VERSION "created by canmatrix"

NS_ :

BS_:

BU_: BMS BMU

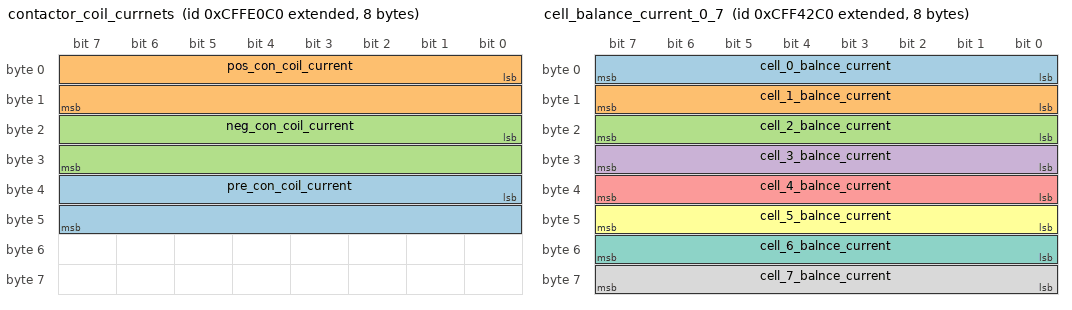
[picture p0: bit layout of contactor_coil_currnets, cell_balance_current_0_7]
BO_ 2365579456 contactor_coil_currnets: 8 Vector__XXX
 SG_ pre_con_coil_current : 32|16@1+ (0.001,0) [0|65.535] "A" Vector__XXX
 SG_ pos_con_coil_current : 0|16@1+ (0.001,0) [0|65.535] "A" Vector__XXX
 SG_ neg_con_coil_current : 16|16@1+ (0.001,0) [0|65.535] "A" Vector__XXX

BO_ 2365583552 safety_app_faults_1: 8 Vector__XXX
 SG_ f_UnprivilegedApplication : 20|1@1+ (1,0) [0|1] "" Vector__XXX
 SG_ f_ServiceDisconnect : 19|1@1+ (1,0) [0|1] "" Vector__XXX
 SG_ f_PackUndervoltage : 5|1@1+ (1,0) [0|1] "" Vector__XXX
 SG_ f_PackOvervoltage : 4|1@1+ (1,0) [0|1] "" Vector__XXX
 SG_ f_PackOvercurrentDischarge : 7|1@1+ (1,0) [0|1] "" Vector__XXX
 SG_ f_PackOvercurrentCharge : 6|1@1+ (1,0) [0|1] "" Vector__XXX
 SG_ f_MasterBoard : 13|1@1+ (1,0) [0|1] "" Vector__XXX
 SG_ f_IsolationLeakage : 12|1@1+ (1,0) [0|1] "" Vector__XXX
 SG_ f_ImminentContactorOpening : 17|1@1+ (1,0) [0|1] "" Vector__XXX
 SG_ f_Hvil : 10|1@1+ (1,0) [0|1] "" Vector__XXX
 SG_ f_FailedVoltage : 9|1@1+ (1,0) [0|1] "" Vector__XXX
 SG_ f_FailedThermistor : 8|1@1+ (1,0) [0|1] "" Vector__XXX
 SG_ f_EStop : 18|1@1+ (1,0) [0|1] "" Vector__XXX
 SG_ f_ContactorWelded : 16|1@1+ (1,0) [0|1] "" Vector__XXX
 SG_ f_ContactorOpen : 15|1@1+ (1,0) [0|1] "" Vector__XXX
 SG_ f_Communication : 11|1@1+ (1,0) [0|1] "" Vector__XXX
 SG_ f_CommandTimeout : 14|1@1+ (1,0) [0|1] "" Vector__XXX
 SG_ f_CellUndervoltage : 1|1@1+ (1,0) [0|1] "" Vector__XXX
 SG_ f_CellUndertemp : 3|1@1+ (1,0) [0|1] "" Vector__XXX
 SG_ f_CellOvervoltage : 0|1@1+ (1,0) [0|1] "" Vector__XXX
 SG_ f_CellOvertemp : 2|1@1+ (1,0) [0|1] "" Vector__XXX

BO_ 2365539008 cell_balance_current_0_7: 8 Vector__XXX
 SG_ cell_0_balnce_current : 0|8@1+ (0.05,0) [0|12.75] "A" Vector__XXX
 SG_ cell_1_balnce_current : 8|8@1+ (0.05,0) [0|12.75] "A" Vector__XXX
 SG_ cell_2_balnce_current : 16|8@1+ (0.05,0) [0|12.75] "A" Vector__XXX
 SG_ cell_3_balnce_current : 24|8@1+ (0.05,0) [0|12.75] "A" Vector__XXX
 SG_ cell_4_balnce_current : 32|8@1+ (0.05,0) [0|12.75] "A" Vector__XXX
 SG_ cell_5_balnce_current : 40|8@1+ (0.05,0) [0|12.75] "A" Vector__XXX
 SG_ cell_6_balnce_current : 48|8@1+ (0.05,0) [0|12.75] "A" Vector__XXX
 SG_ cell_7_balnce_current : 56|8@1+ (0.05,0) [0|12.75] "A" Vector__XXX

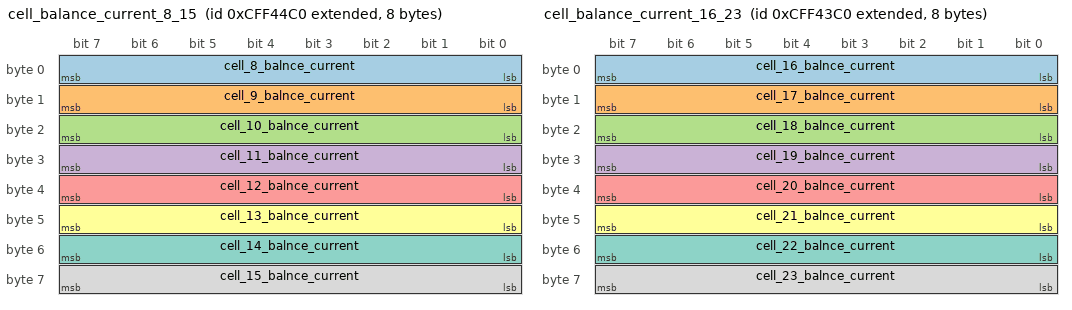
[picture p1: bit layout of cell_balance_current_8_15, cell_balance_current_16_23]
BO_ 2365539520 cell_balance_current_8_15: 8 Vector__XXX
 SG_ cell_8_balnce_current : 0|8@1+ (0.05,0) [0|12.75] "A" Vector__XXX
 SG_ cell_9_balnce_current : 8|8@1+ (0.05,0) [0|12.75] "A" Vector__XXX
 SG_ cell_10_balnce_current : 16|8@1+ (0.05,0) [0|12.75] "A" Vector__XXX
 SG_ cell_11_balnce_current : 24|8@1+ (0.05,0) [0|12.75] "A" Vector__XXX
 SG_ cell_12_balnce_current : 32|8@1+ (0.05,0) [0|12.75] "A" Vector__XXX
 SG_ cell_13_balnce_current : 40|8@1+ (0.05,0) [0|12.75] "A" Vector__XXX
 SG_ cell_14_balnce_current : 48|8@1+ (0.05,0) [0|12.75] "A" Vector__XXX
 SG_ cell_15_balnce_current : 56|8@1+ (0.05,0) [0|12.75] "A" Vector__XXX

BO_ 2365539264 cell_balance_current_16_23: 8 Vector__XXX
 SG_ cell_16_balnce_current : 0|8@1+ (0.05,0) [0|12.75] "A" Vector__XXX
 SG_ cell_17_balnce_current : 8|8@1+ (0.05,0) [0|12.75] "A" Vector__XXX
 SG_ cell_18_balnce_current : 16|8@1+ (0.05,0) [0|12.75] "A" Vector__XXX
 SG_ cell_19_balnce_current : 24|8@1+ (0.05,0) [0|12.75] "A" Vector__XXX
 SG_ cell_20_balnce_current : 32|8@1+ (0.05,0) [0|12.75] "A" Vector__XXX
 SG_ cell_21_balnce_current : 40|8@1+ (0.05,0) [0|12.75] "A" Vector__XXX
 SG_ cell_22_balnce_current : 48|8@1+ (0.05,0) [0|12.75] "A" Vector__XXX
 SG_ cell_23_balnce_current : 56|8@1+ (0.05,0) [0|12.75] "A" Vector__XXX

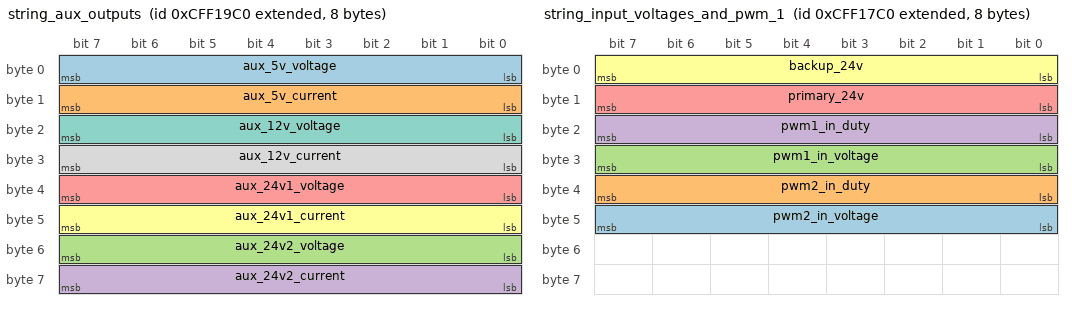
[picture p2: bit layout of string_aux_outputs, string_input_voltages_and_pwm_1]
BO_ 2365528512 string_aux_outputs: 8 Vector__XXX
 SG_ aux_5v_voltage : 0|8@1+ (0.15,0) [0|38.25] "A" Vector__XXX
 SG_ aux_5v_current : 8|8@1+ (0.15,0) [0|38.25] "A" Vector__XXX
 SG_ aux_24v2_voltage : 48|8@1+ (0.15,0) [0|38.25] "A" Vector__XXX
 SG_ aux_24v2_current : 56|8@1+ (0.15,0) [0|38.25] "A" Vector__XXX
 SG_ aux_24v1_voltage : 32|8@1+ (0.15,0) [0|38.25] "A" Vector__XXX
 SG_ aux_24v1_current : 40|8@1+ (0.15,0) [0|38.25] "A" Vector__XXX
 SG_ aux_12v_voltage : 16|8@1+ (0.15,0) [0|38.25] "A" Vector__XXX
 SG_ aux_12v_current : 24|8@1+ (0.15,0) [0|38.25] "A" Vector__XXX

BO_ 2365528256 string_input_voltages_and_pwm_2: 8 Vector__XXX
 SG_ pwm2_in_freq : 32|32@1+ (1,0) [0|65535] "A" Vector__XXX
 SG_ pwm1_in_freq : 0|32@1+ (1,0) [0|65535] "A" Vector__XXX

BO_ 2365528000 string_input_voltages_and_pwm_1: 8 Vector__XXX
 SG_ pwm2_in_voltage : 40|8@1+ (0.15,0) [0|38.25] "A" Vector__XXX
 SG_ pwm2_in_duty : 32|8@1+ (0.5,0) [0|127.5] "A" Vector__XXX
 SG_ pwm1_in_voltage : 24|8@1+ (0.15,0) [0|38.25] "A" Vector__XXX
 SG_ pwm1_in_duty : 16|8@1+ (0.5,0) [0|127.5] "A" Vector__XXX
 SG_ primary_24v : 8|8@1+ (0.15,0) [0|38.25] "A" Vector__XXX
 SG_ backup_24v : 0|8@1+ (0.15,0) [0|38.25] "A" Vector__XXX

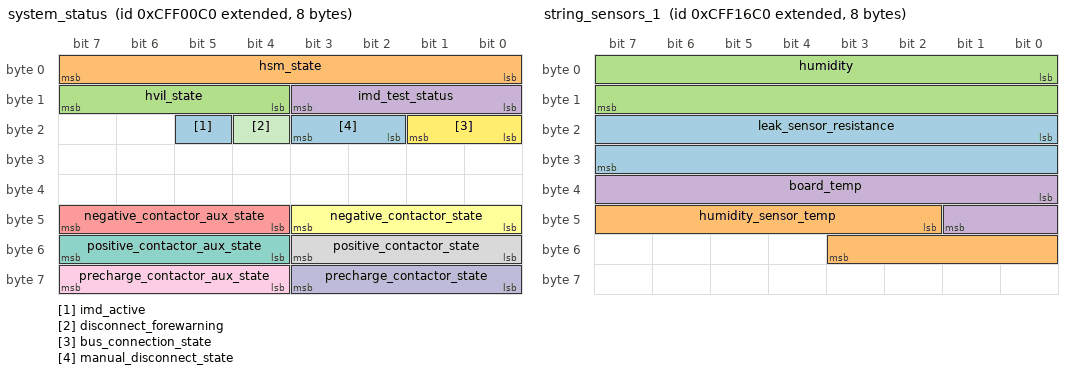
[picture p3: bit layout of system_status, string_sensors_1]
BO_ 2365522112 system_status: 8 BMS
 SG_ imd_active : 21|1@1+ (1,0) [0|1] "C" Vector__XXX
 SG_ hsm_state : 0|8@1+ (1,0) [0|255] ""  BMU
 SG_ hvil_state : 12|4@1+ (1,0) [0|15] ""  BMU
 SG_ imd_test_status : 8|4@1+ (1,0) [0|15] ""  BMU
 SG_ negative_contactor_aux_state : 44|4@1+ (1,0) [0|15] ""  BMU
 SG_ negative_contactor_state : 40|4@1+ (1,0) [0|15] ""  BMU
 SG_ positive_contactor_aux_state : 52|4@1+ (1,0) [0|15] ""  BMU
 SG_ positive_contactor_state : 48|4@1+ (1,0) [0|15] ""  BMU
 SG_ precharge_contactor_aux_state : 60|4@1+ (1,0) [0|15] ""  BMU
 SG_ precharge_contactor_state : 56|4@1+ (1,0) [0|15] ""  BMU
 SG_ disconnect_forewarning : 20|1@1+ (1,0) [0|1] ""  BMU
 SG_ bus_connection_state : 16|2@1+ (1,0) [0|3] "" Vector__XXX
 SG_ manual_disconnect_state : 18|2@1+ (1,0) [0|3] "" Vector__XXX

BO_ 2365527744 string_sensors_1: 8 Vector__XXX
 SG_ leak_sensor_resistance : 16|16@1+ (0.0025,0) [0|163.8375] "" Vector__XXX
 SG_ humidity_sensor_temp : 42|10@1+ (0.2,-50) [-50|154.6] "" Vector__XXX
 SG_ humidity : 0|16@1+ (0.0025,0) [0|163.8375] "" Vector__XXX
 SG_ board_temp : 32|10@1+ (0.2,-50) [-50|154.6] "" Vector__XXX

BO_ 2365527488 string_ntc_temps_7_8: 8 Vector__XXX
 SG_ ntc_temp_8 : 20|10@1+ (0.2,-50) [-50|154.6] "" Vector__XXX
 SG_ ntc_temp_7 : 10|10@1+ (0.2,-50) [-50|154.6] "" Vector__XXX

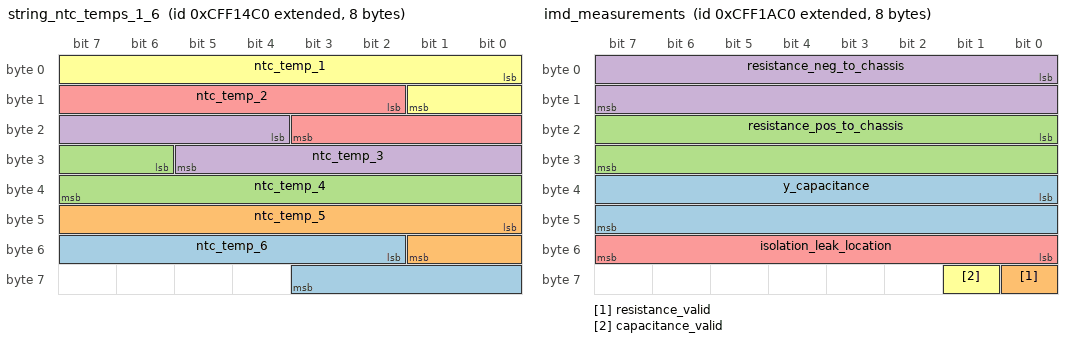
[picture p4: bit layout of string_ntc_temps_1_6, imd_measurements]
BO_ 2365527232 string_ntc_temps_1_6: 8 Vector__XXX
 SG_ ntc_temp_6 : 50|10@1+ (0.2,-50) [-50|154.6] "" Vector__XXX
 SG_ ntc_temp_5 : 40|10@1+ (0.2,-50) [-50|154.6] "" Vector__XXX
 SG_ ntc_temp_4 : 30|10@1+ (0.2,-50) [-50|154.6] "" Vector__XXX
 SG_ ntc_temp_3 : 20|10@1+ (0.2,-50) [-50|154.6] "" Vector__XXX
 SG_ ntc_temp_2 : 10|10@1+ (0.2,-50) [-50|154.6] "" Vector__XXX
 SG_ ntc_temp_1 : 0|10@1+ (0.2,-50) [-50|154.6] "" Vector__XXX

BO_ 2365528768 imd_measurements: 8 Vector__XXX
 SG_ y_capacitance : 32|16@1+ (1,0) [0|65535] "A" Vector__XXX
 SG_ resistance_valid : 56|1@1+ (1,0) [0|1] "C" Vector__XXX
 SG_ resistance_pos_to_chassis : 16|16@1+ (100,0) [0|6553500] "A" Vector__XXX
 SG_ resistance_neg_to_chassis : 0|16@1+ (100,0) [0|6553500] "A" Vector__XXX
 SG_ isolation_leak_location : 48|8@1+ (0.005,0) [0|1.275] "" Vector__XXX
 SG_ capacitance_valid : 57|1@1+ (1,0) [0|1] "C" Vector__XXX

BO_ 2365538752 cell_balancing_status_0_23: 8 Vector__XXX
 SG_ cell_0_balance_status : 0|1@1+ (1,0) [0|1] "" Vector__XXX
 SG_ cell_1_balance_status : 1|1@1+ (1,0) [0|1] "" Vector__XXX
 SG_ cell_2_balance_status : 2|1@1+ (1,0) [0|1] "" Vector__XXX
 SG_ cell_3_balance_status : 3|1@1+ (1,0) [0|1] "" Vector__XXX
 SG_ cell_4_balance_status : 4|1@1+ (1,0) [0|1] "" Vector__XXX
 SG_ cell_5_balance_status : 5|1@1+ (1,0) [0|1] "" Vector__XXX
 SG_ cell_6_balance_status : 6|1@1+ (1,0) [0|1] "" Vector__XXX
 SG_ cell_7_balance_status : 7|1@1+ (1,0) [0|1] "" Vector__XXX
 SG_ cell_8_balance_status : 8|1@1+ (1,0) [0|1] "" Vector__XXX
 SG_ cell_9_balance_status : 9|1@1+ (1,0) [0|1] "" Vector__XXX
 SG_ cell_10_balance_status : 10|1@1+ (1,0) [0|1] "" Vector__XXX
 SG_ cell_11_balance_status : 11|1@1+ (1,0) [0|1] "" Vector__XXX
 SG_ cell_12_balance_status : 12|1@1+ (1,0) [0|1] "" Vector__XXX
 SG_ cell_13_balance_status : 13|1@1+ (1,0) [0|1] "" Vector__XXX
 SG_ cell_14_balance_status : 14|1@1+ (1,0) [0|1] "" Vector__XXX
 SG_ cell_15_balance_status : 15|1@1+ (1,0) [0|1] "" Vector__XXX
 SG_ cell_16_balance_status : 16|1@1+ (1,0) [0|1] "" Vector__XXX
 SG_ cell_17_balance_status : 17|1@1+ (1,0) [0|1] "" Vector__XXX
 SG_ cell_18_balance_status : 18|1@1+ (1,0) [0|1] "" Vector__XXX
 SG_ cell_19_balance_status : 19|1@1+ (1,0) [0|1] "" Vector__XXX
 SG_ cell_20_balance_status : 20|1@1+ (1,0) [0|1] "" Vector__XXX
 SG_ cell_21_balance_status : 21|1@1+ (1,0) [0|1] "" Vector__XXX
 SG_ cell_22_balance_status : 22|1@1+ (1,0) [0|1] "" Vector__XXX
 SG_ cell_23_balance_status : 23|1@1+ (1,0) [0|1] "" Vector__XXX

BO_ 2365538496 cell_balancing_commands_0_23: 8 Vector__XXX
 SG_ cell_0_balance_command : 0|1@1+ (1,0) [0|1] "" Vector__XXX
 SG_ cell_1_balance_command : 1|1@1+ (1,0) [0|1] "" Vector__XXX
 SG_ cell_2_balance_command : 2|1@1+ (1,0) [0|1] "" Vector__XXX
 SG_ cell_3_balance_command : 3|1@1+ (1,0) [0|1] "" Vector__XXX
 SG_ cell_4_balance_command : 4|1@1+ (1,0) [0|1] "" Vector__XXX
 SG_ cell_5_balance_command : 5|1@1+ (1,0) [0|1] "" Vector__XXX
 SG_ cell_6_balance_command : 6|1@1+ (1,0) [0|1] "" Vector__XXX
 SG_ cell_7_balance_command : 7|1@1+ (1,0) [0|1] "" Vector__XXX
 SG_ cell_8_balance_command : 8|1@1+ (1,0) [0|1] "" Vector__XXX
 SG_ cell_9_balance_command : 9|1@1+ (1,0) [0|1] "" Vector__XXX
 SG_ cell_10_balance_command : 10|1@1+ (1,0) [0|1] "" Vector__XXX
 SG_ cell_11_balance_command : 11|1@1+ (1,0) [0|1] "" Vector__XXX
 SG_ cell_12_balance_command : 12|1@1+ (1,0) [0|1] "" Vector__XXX
 SG_ cell_13_balance_command : 13|1@1+ (1,0) [0|1] "" Vector__XXX
 SG_ cell_14_balance_command : 14|1@1+ (1,0) [0|1] "" Vector__XXX
 SG_ cell_15_balance_command : 15|1@1+ (1,0) [0|1] "" Vector__XXX
 SG_ cell_16_balance_command : 16|1@1+ (1,0) [0|1] "" Vector__XXX
 SG_ cell_17_balance_command : 17|1@1+ (1,0) [0|1] "" Vector__XXX
 SG_ cell_18_balance_command : 18|1@1+ (1,0) [0|1] "" Vector__XXX
 SG_ cell_19_balance_command : 19|1@1+ (1,0) [0|1] "" Vector__XXX
 SG_ cell_20_balance_command : 20|1@1+ (1,0) [0|1] "" Vector__XXX
 SG_ cell_21_balance_command : 21|1@1+ (1,0) [0|1] "" Vector__XXX
 SG_ cell_22_balance_command : 22|1@1+ (1,0) [0|1] "" Vector__XXX
 SG_ cell_23_balance_command : 23|1@1+ (1,0) [0|1] "" Vector__XXX

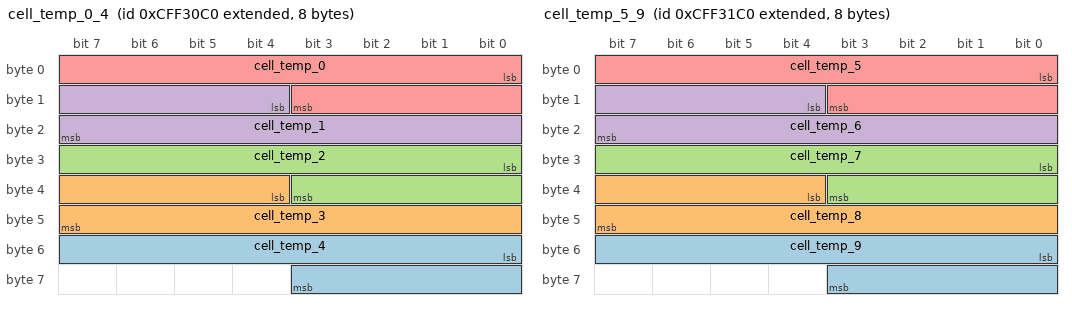
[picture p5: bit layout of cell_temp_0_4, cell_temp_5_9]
BO_ 2365534400 cell_temp_0_4: 8 Vector__XXX
 SG_ cell_temp_4 : 48|12@1+ (0.05,-50) [-50|154.75] "" Vector__XXX
 SG_ cell_temp_3 : 36|12@1+ (0.05,-50) [-50|154.75] "" Vector__XXX
 SG_ cell_temp_2 : 24|12@1+ (0.05,-50) [-50|154.75] "" Vector__XXX
 SG_ cell_temp_1 : 12|12@1+ (0.05,-50) [-50|154.75] "" Vector__XXX
 SG_ cell_temp_0 : 0|12@1+ (0.05,-50) [-50|154.75] "" Vector__XXX

BO_ 2365534656 cell_temp_5_9: 8 Vector__XXX
 SG_ cell_temp_9 : 48|12@1+ (0.05,-50) [-50|154.75] "" Vector__XXX
 SG_ cell_temp_8 : 36|12@1+ (0.05,-50) [-50|154.75] "" Vector__XXX
 SG_ cell_temp_7 : 24|12@1+ (0.05,-50) [-50|154.75] "" Vector__XXX
 SG_ cell_temp_6 : 12|12@1+ (0.05,-50) [-50|154.75] "" Vector__XXX
 SG_ cell_temp_5 : 0|12@1+ (0.05,-50) [-50|154.75] "" Vector__XXX

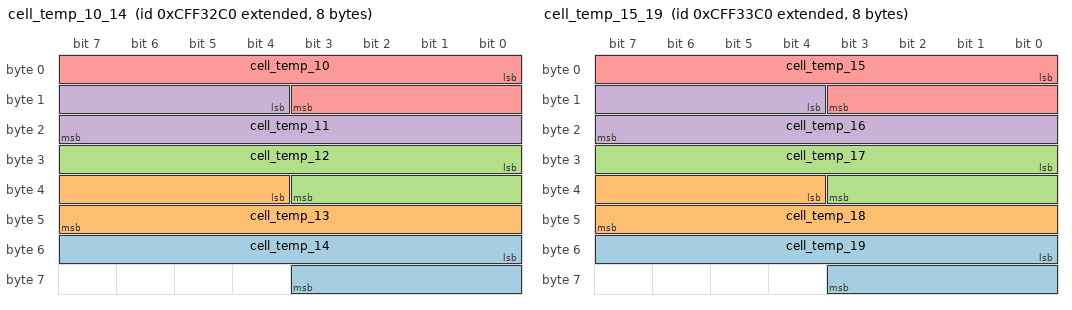
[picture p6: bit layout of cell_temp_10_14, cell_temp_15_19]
BO_ 2365534912 cell_temp_10_14: 8 Vector__XXX
 SG_ cell_temp_14 : 48|12@1+ (0.05,-50) [-50|154.75] "" Vector__XXX
 SG_ cell_temp_13 : 36|12@1+ (0.05,-50) [-50|154.75] "" Vector__XXX
 SG_ cell_temp_12 : 24|12@1+ (0.05,-50) [-50|154.75] "" Vector__XXX
 SG_ cell_temp_11 : 12|12@1+ (0.05,-50) [-50|154.75] "" Vector__XXX
 SG_ cell_temp_10 : 0|12@1+ (0.05,-50) [-50|154.75] "" Vector__XXX

BO_ 2365535168 cell_temp_15_19: 8 Vector__XXX
 SG_ cell_temp_19 : 48|12@1+ (0.05,-50) [-50|154.75] "" Vector__XXX
 SG_ cell_temp_18 : 36|12@1+ (0.05,-50) [-50|154.75] "" Vector__XXX
 SG_ cell_temp_17 : 24|12@1+ (0.05,-50) [-50|154.75] "" Vector__XXX
 SG_ cell_temp_16 : 12|12@1+ (0.05,-50) [-50|154.75] "" Vector__XXX
 SG_ cell_temp_15 : 0|12@1+ (0.05,-50) [-50|154.75] "" Vector__XXX

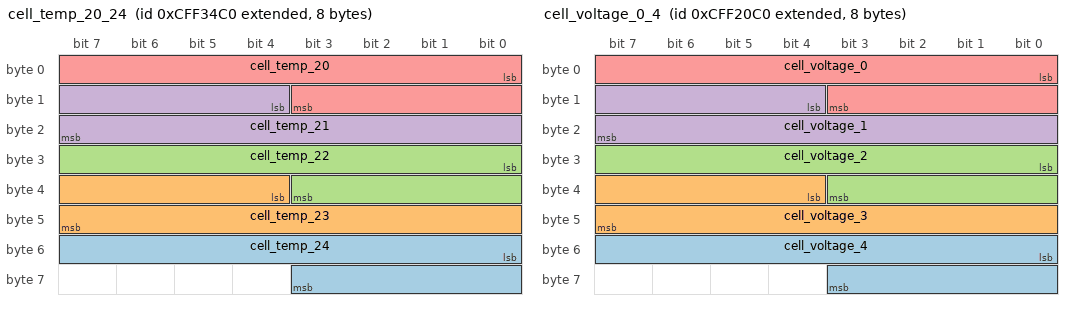
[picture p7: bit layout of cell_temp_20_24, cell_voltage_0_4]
BO_ 2365535424 cell_temp_20_24: 8 Vector__XXX
 SG_ cell_temp_24 : 48|12@1+ (0.05,-50) [-50|154.75] "" Vector__XXX
 SG_ cell_temp_23 : 36|12@1+ (0.05,-50) [-50|154.75] "" Vector__XXX
 SG_ cell_temp_22 : 24|12@1+ (0.05,-50) [-50|154.75] "" Vector__XXX
 SG_ cell_temp_21 : 12|12@1+ (0.05,-50) [-50|154.75] "" Vector__XXX
 SG_ cell_temp_20 : 0|12@1+ (0.05,-50) [-50|154.75] "" Vector__XXX

BO_ 2365530304 cell_voltage_0_4: 8 Vector__XXX
 SG_ cell_voltage_4 : 48|12@1+ (0.05,-50) [-50|154.75] "" Vector__XXX
 SG_ cell_voltage_3 : 36|12@1+ (0.05,-50) [-50|154.75] "" Vector__XXX
 SG_ cell_voltage_2 : 24|12@1+ (0.05,-50) [-50|154.75] "" Vector__XXX
 SG_ cell_voltage_1 : 12|12@1+ (0.05,-50) [-50|154.75] "" Vector__XXX
 SG_ cell_voltage_0 : 0|12@1+ (0.05,-50) [-50|154.75] "" Vector__XXX

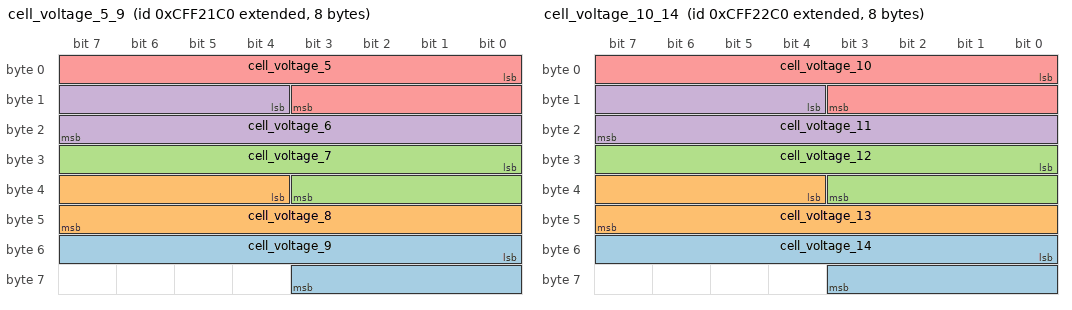
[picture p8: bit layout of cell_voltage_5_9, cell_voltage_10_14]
BO_ 2365530560 cell_voltage_5_9: 8 Vector__XXX
 SG_ cell_voltage_9 : 48|12@1+ (0.05,-50) [-50|154.75] "" Vector__XXX
 SG_ cell_voltage_8 : 36|12@1+ (0.05,-50) [-50|154.75] "" Vector__XXX
 SG_ cell_voltage_7 : 24|12@1+ (0.05,-50) [-50|154.75] "" Vector__XXX
 SG_ cell_voltage_6 : 12|12@1+ (0.05,-50) [-50|154.75] "" Vector__XXX
 SG_ cell_voltage_5 : 0|12@1+ (0.05,-50) [-50|154.75] "" Vector__XXX

BO_ 2365530816 cell_voltage_10_14: 8 Vector__XXX
 SG_ cell_voltage_14 : 48|12@1+ (0.05,-50) [-50|154.75] "" Vector__XXX
 SG_ cell_voltage_13 : 36|12@1+ (0.05,-50) [-50|154.75] "" Vector__XXX
 SG_ cell_voltage_12 : 24|12@1+ (0.05,-50) [-50|154.75] "" Vector__XXX
 SG_ cell_voltage_11 : 12|12@1+ (0.05,-50) [-50|154.75] "" Vector__XXX
 SG_ cell_voltage_10 : 0|12@1+ (0.05,-50) [-50|154.75] "" Vector__XXX

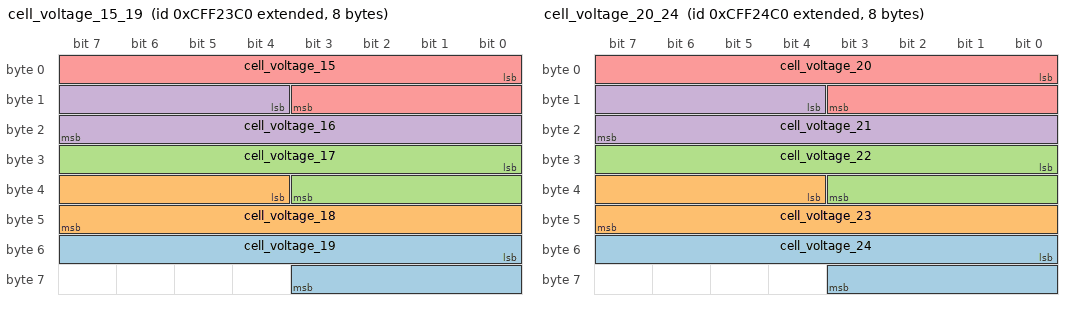
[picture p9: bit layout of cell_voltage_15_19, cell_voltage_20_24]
BO_ 2365531072 cell_voltage_15_19: 8 Vector__XXX
 SG_ cell_voltage_19 : 48|12@1+ (0.05,-50) [-50|154.75] "" Vector__XXX
 SG_ cell_voltage_18 : 36|12@1+ (0.05,-50) [-50|154.75] "" Vector__XXX
 SG_ cell_voltage_17 : 24|12@1+ (0.05,-50) [-50|154.75] "" Vector__XXX
 SG_ cell_voltage_16 : 12|12@1+ (0.05,-50) [-50|154.75] "" Vector__XXX
 SG_ cell_voltage_15 : 0|12@1+ (0.05,-50) [-50|154.75] "" Vector__XXX

BO_ 2365531328 cell_voltage_20_24: 8 Vector__XXX
 SG_ cell_voltage_24 : 48|12@1+ (0.05,-50) [-50|154.75] "" Vector__XXX
 SG_ cell_voltage_23 : 36|12@1+ (0.05,-50) [-50|154.75] "" Vector__XXX
 SG_ cell_voltage_22 : 24|12@1+ (0.05,-50) [-50|154.75] "" Vector__XXX
 SG_ cell_voltage_21 : 12|12@1+ (0.05,-50) [-50|154.75] "" Vector__XXX
 SG_ cell_voltage_20 : 0|12@1+ (0.05,-50) [-50|154.75] "" Vector__XXX

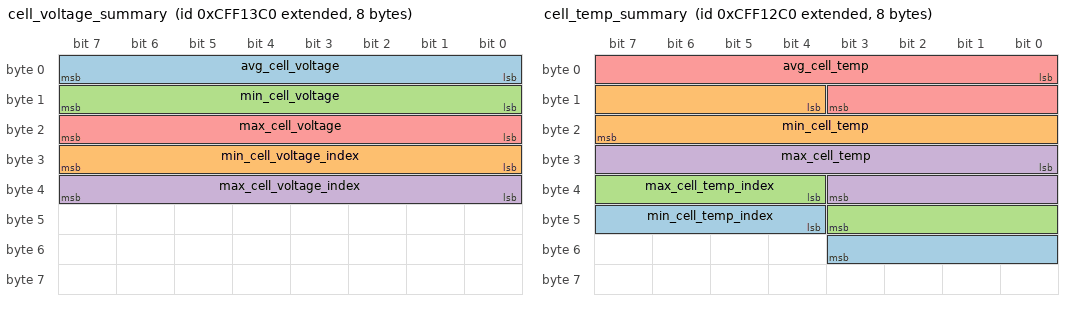
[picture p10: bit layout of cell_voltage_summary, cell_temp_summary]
BO_ 2365526976 cell_voltage_summary: 8 BMS
 SG_ avg_cell_voltage : 0|8@1+ (0.05,0) [0|12.75] "A"  BMU
 SG_ min_cell_voltage_index : 24|8@1+ (1,0) [0|255] "A"  BMU
 SG_ min_cell_voltage : 8|8@1+ (0.05,0) [0|12.75] "A"  BMU
 SG_ max_cell_voltage_index : 32|8@1+ (1,0) [0|255] ""  BMU
 SG_ max_cell_voltage : 16|8@1+ (0.05,0) [0|12.75] "A"  BMU

BO_ 2365526720 cell_temp_summary: 8 BMS
 SG_ min_cell_temp_index : 44|8@1+ (1,0) [0|255] "A"  BMU
 SG_ min_cell_temp : 12|12@1+ (0.1,0) [0|409.5] "C"  BMU
 SG_ max_cell_temp_index : 36|8@1+ (1,0) [0|255] ""  BMU
 SG_ max_cell_temp : 24|12@1+ (0.1,0) [0|409.5] "C"  BMU
 SG_ avg_cell_temp : 0|12@1+ (0.1,0) [0|409.5] "C"  BMU

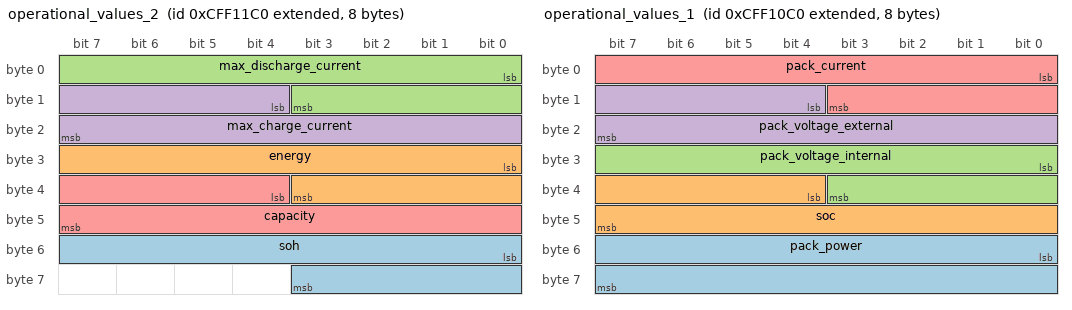
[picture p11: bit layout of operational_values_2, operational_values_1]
BO_ 2365526464 operational_values_2: 8 BMS
 SG_ soh : 48|12@1+ (0.025,0) [0|102.375] ""  BMU
 SG_ energy : 24|12@1+ (0.25,0) [0|1023.75] "Ah"  BMU
 SG_ max_discharge_current : 0|12@1+ (0.25,0) [0|1023.75] "A"  BMU
 SG_ max_charge_current : 12|12@1+ (0.25,0) [0|1023.75] "A"  BMU
 SG_ capacity : 36|12@1+ (0.25,0) [0|1023.75] "Ah"  BMU

BO_ 2365526208 operational_values_1: 8 BMS
 SG_ pack_power : 48|16@1+ (0.01,0) [0|655.35] "klW"  BMU
 SG_ soc : 36|12@1+ (0.025,0) [0|102.375] ""  BMU
 SG_ pack_voltage_internal : 24|12@1+ (0.25,0) [0|1023.75] "V"  BMU
 SG_ pack_voltage_external : 12|12@1+ (0.25,0) [0|1023.75] "V"  BMU
 SG_ pack_current : 0|12@1+ (0.25,0) [0|1023.75] "A"  BMU

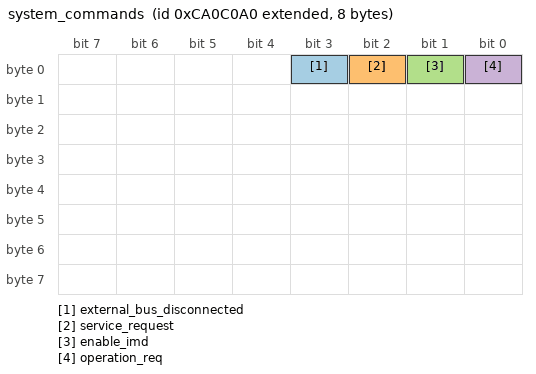
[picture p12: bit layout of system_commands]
BO_ 2359345312 system_commands: 8 BMU
 SG_ external_bus_disconnected : 3|1@1+ (1,0) [0|1] ""  BMS
 SG_ service_request : 2|1@1+ (1,0) [0|1] ""  BMS
 SG_ enable_imd : 1|1@1+ (1,0) [0|1] ""  BMS
 SG_ operation_req : 0|1@1+ (1,0) [0|1] ""  BMS

BA_DEF_ BO_  "VFrameFormat" ENUM  "StandardCAN","ExtendedCAN","reserved","J1939PG";
BA_DEF_ SG_  "GenSigStartValue" FLOAT 0 100000000000;
BA_DEF_  "ProtocolType" STRING ;
BA_DEF_ BO_  "CanDootDecode" ENUM  "No","Yes";
BA_DEF_ BO_  "CanDootDecodeBus" INT 0 6;
BA_DEF_ BO_  "CanDootSimulate" ENUM  "No","Yes";
BA_DEF_ BO_  "CanDootSimulateBus" INT 0 6;
BA_DEF_ BO_  "CanDootSimulateCycleTime" INT 0 50000;
BA_DEF_ BO_  "CG_RX_TX" ENUM  "RX","TX","NONE";
BA_DEF_ SG_  "CanDootBroadcast" ENUM  "No","Yes";
BA_DEF_ SG_  "CG_VarType" ENUM  "bool","uint8_t","int8_t","uint16_t","int16_t","uint32_t","int32_t","float","double";
BA_DEF_DEF_  "VFrameFormat" "";
BA_DEF_DEF_  "GenSigStartValue" 0;
BA_DEF_DEF_  "ProtocolType" "";
BA_DEF_DEF_  "CanDootDecode" "Yes";
BA_DEF_DEF_  "CanDootDecodeBus" 1;
BA_DEF_DEF_  "CanDootSimulate" "No";
BA_DEF_DEF_  "CanDootSimulateBus" 1;
BA_DEF_DEF_  "CanDootSimulateCycleTime" 100;
BA_DEF_DEF_  "CG_RX_TX" "RX";
BA_DEF_DEF_  "CanDootBroadcast" "Yes";
BA_DEF_DEF_  "CG_VarType" "uint8_t";
BA_ "ProtocolType" "J1939";
BA_ "VFrameFormat" BO_ 2365579456 3;
BA_ "VFrameFormat" BO_ 2365583552 3;
BA_ "VFrameFormat" BO_ 2365539008 3;
BA_ "VFrameFormat" BO_ 2365539520 3;
BA_ "VFrameFormat" BO_ 2365539264 3;
BA_ "VFrameFormat" BO_ 2365528512 3;
BA_ "VFrameFormat" BO_ 2365528256 3;
BA_ "VFrameFormat" BO_ 2365528000 3;
BA_ "VFrameFormat" BO_ 2365522112 3;
BA_ "VFrameFormat" BO_ 2365527744 3;
BA_ "VFrameFormat" BO_ 2365527488 3;
BA_ "VFrameFormat" BO_ 2365527232 3;
BA_ "VFrameFormat" BO_ 2365528768 3;
BA_ "VFrameFormat" BO_ 2365538752 3;
BA_ "VFrameFormat" BO_ 2365538496 3;
BA_ "VFrameFormat" BO_ 2365534400 3;
BA_ "VFrameFormat" BO_ 2365534656 3;
BA_ "VFrameFormat" BO_ 2365534912 3;
BA_ "VFrameFormat" BO_ 2365535168 3;
BA_ "VFrameFormat" BO_ 2365535424 3;
BA_ "VFrameFormat" BO_ 2365530304 3;
BA_ "VFrameFormat" BO_ 2365530560 3;
BA_ "VFrameFormat" BO_ 2365530816 3;
BA_ "VFrameFormat" BO_ 2365531072 3;
BA_ "VFrameFormat" BO_ 2365531328 3;
BA_ "VFrameFormat" BO_ 2365526976 3;
BA_ "VFrameFormat" BO_ 2365526720 3;
BA_ "VFrameFormat" BO_ 2365526464 3;
BA_ "VFrameFormat" BO_ 2365526208 3;
BA_ "CanDootDecode" BO_ 2359345312 0;
BA_ "CanDootSimulate" BO_ 2359345312 1;
BA_ "VFrameFormat" BO_ 2359345312 3;
BA_ "GenSigStartValue" SG_ 2365527744 humidity_sensor_temp 250;
BA_ "GenSigStartValue" SG_ 2365527744 board_temp 250;
BA_ "GenSigStartValue" SG_ 2365527488 ntc_temp_8 250;
BA_ "GenSigStartValue" SG_ 2365527488 ntc_temp_7 250;
BA_ "GenSigStartValue" SG_ 2365527232 ntc_temp_6 250;
BA_ "GenSigStartValue" SG_ 2365527232 ntc_temp_5 250;
BA_ "GenSigStartValue" SG_ 2365527232 ntc_temp_4 250;
BA_ "GenSigStartValue" SG_ 2365527232 ntc_temp_3 250;
BA_ "GenSigStartValue" SG_ 2365527232 ntc_temp_2 250;
BA_ "GenSigStartValue" SG_ 2365527232 ntc_temp_1 250;
BA_ "GenSigStartValue" SG_ 2365534400 cell_temp_4 1000;
BA_ "GenSigStartValue" SG_ 2365534400 cell_temp_3 1000;
BA_ "GenSigStartValue" SG_ 2365534400 cell_temp_2 1000;
BA_ "GenSigStartValue" SG_ 2365534400 cell_temp_1 1000;
BA_ "GenSigStartValue" SG_ 2365534400 cell_temp_0 1000;
VAL_ 2365522112 hsm_state 0 "TOP" 1 "REGULAR_OPERATION" 2 "INIT" 3 "IMD_TEST" 4 "STANDBY" 5 "HV_OPERATION" 6 "PRECHARGE" 7 "DISABLE_IMD" 8 "START_PRECHARGE_ATTEMPT" 9 "CLOSE_NEGATIVE_CONTACTOR" 10 "CLOSE_PRECHARGE_CONTACTOR" 11 "PRECHARGE_DELAY" 12 "CLOSE_POSITIVE_CONTACTOR" 13 "OPEN_PRECHARGE_CONTACTOR" 14 "HV_READY" 15 "ABORT_PRECHARGE_ATTEMPT" 16 "AP_OPEN_PRE_POS_CON" 17 "AP_OPEN_NEG_CON" 18 "PRECHARGE_RESTART_DELAY" 19 "SERVICE" 20 "SLEEP" 21 "NORMAL_SHUTDOWN" 22 "NS_OPEN_PRE_POS_CON" 23 "NS_OPEN_NEG_CON" 24 "CONTROLLED_SHUTDOWN" 25 "CS_OPEN_PRE_POS_CON" 26 "CS_OPEN_NEG_CON" 27 "EMERGENCY_SHUTDOWN" 28 "ES_OPEN_PRE_POS_CON" 29 "ES_OPEN_NEG_CON" 30 "FAULTED_STANDBY" ;
VAL_ 2365522112 hvil_state 0 "ErrorInvalidFrequency" 1 "ErrorInvalidDutyCycle" 2 "ErrorLossOfSignal" 3 "ErrorDutyCycleMismatch" 4 "ErrorFrequencyMismatch" 5 "ErrorSize" 6 "Connected" ;
VAL_ 2365522112 imd_test_status 0 "Inactive" 1 "InProgress" ;
VAL_ 2365522112 negative_contactor_aux_state 0 "kDeasserted" 1 "kAsserted" ;
VAL_ 2365522112 negative_contactor_state 0 "kInit" 1 "kOpen" 2 "kClosing" 3 "kClosed" 4 "kOpening" 5 "kFault" ;
VAL_ 2365522112 positive_contactor_aux_state 0 "kDeasserted" 1 "kAsserted" ;
VAL_ 2365522112 positive_contactor_state 0 "kInit" 1 "kOpen" 2 "kClosing" 3 "kClosed" 4 "kOpening" 5 "kFault" ;
VAL_ 2365522112 precharge_contactor_aux_state 0 "kDeasserted" 1 "kAsserted" ;
VAL_ 2365522112 precharge_contactor_state 0 "kInit" 1 "kOpen" 2 "kClosing" 3 "kClosed" 4 "kOpening" 5 "kFault" ;
VAL_ 2365522112 disconnect_forewarning 0 "False" 1 "True" ;
VAL_ 2365522112 bus_connection_state 0 "Disconnected" 1 "Connected" ;
VAL_ 2365522112 manual_disconnect_state 0 "Disconnected" 1 "Connected" ;
VAL_ 2359345312 external_bus_disconnected 0 "False" 1 "True" ;
VAL_ 2359345312 service_request 0 "False" 1 "True" ;
VAL_ 2359345312 enable_imd 0 "False" 1 "True" ;
VAL_ 2359345312 operation_req 0 "False" 1 "True" ;
